VERSION ""

NS_ :

BS_:

BU_:

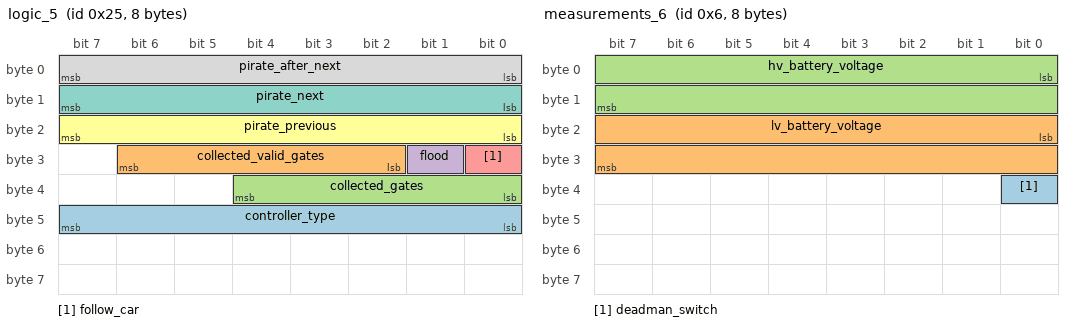
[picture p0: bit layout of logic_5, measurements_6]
BO_ 37 logic_5: 8 Vector__XXX
 SG_ controller_type : 40|8@1+ (1,0) [0|255] "" Vector__XXX
 SG_ collected_valid_gates : 26|5@1+ (1,0) [0|31] "" Vector__XXX
 SG_ collected_gates : 32|5@1+ (1,0) [0|31] "" Vector__XXX
 SG_ flood : 25|1@1+ (1,0) [0|0] "" Vector__XXX
 SG_ follow_car : 24|1@1+ (1,0) [0|0] "" Vector__XXX
 SG_ pirate_previous : 16|8@1+ (1,0) [0|255] "char" Vector__XXX
 SG_ pirate_next : 8|8@1+ (1,0) [0|255] "char" Vector__XXX
 SG_ pirate_after_next : 0|8@1+ (1,0) [0|255] "char" Vector__XXX

BO_ 6 measurements_6: 8 Vector__XXX
 SG_ deadman_switch : 32|1@1+ (1,0) [0|1] "" Vector__XXX
 SG_ lv_battery_voltage : 16|16@1+ (0.00025,0) [0|16.38375] "m" Vector__XXX
 SG_ hv_battery_voltage : 0|16@1+ (0.00025,0) [0|16.38375] "m" Vector__XXX

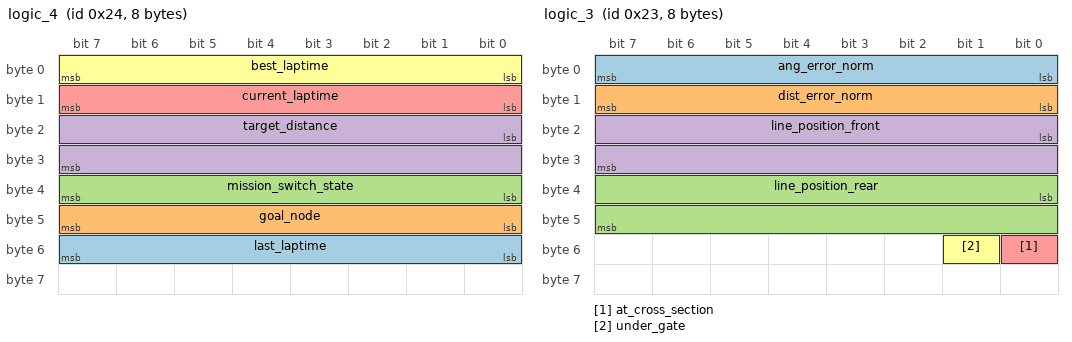
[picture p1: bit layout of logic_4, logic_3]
BO_ 36 logic_4: 8 Vector__XXX
 SG_ last_laptime : 48|8@1+ (0.01,0) [0|2.55] "s" Vector__XXX
 SG_ goal_node : 40|8@1+ (1,0) [0|255] "char" Vector__XXX
 SG_ mission_switch_state : 32|8@1+ (1,0) [0|255] "enum" Vector__XXX
 SG_ target_distance : 16|16@1+ (0.01,-327.675) [-327.675|327.675] "m" Vector__XXX
 SG_ current_laptime : 8|8@1+ (0.01,0) [0|2.55] "s" Vector__XXX
 SG_ best_laptime : 0|8@1+ (0.01,0) [0|2.55] "s" Vector__XXX

BO_ 35 logic_3: 8 Vector__XXX
 SG_ ang_error_norm : 0|8@1+ (0.004,0) [0|1.02] "" Vector__XXX
 SG_ dist_error_norm : 8|8@1+ (0.004,0) [0|1.02] "" Vector__XXX
 SG_ line_position_rear : 32|16@1+ (0.0005,-16.38375) [-16.38375|16.38375] "m" Vector__XXX
 SG_ line_position_front : 16|16@1+ (0.0005,-16.38375) [-16.38375|16.38375] "m" Vector__XXX
 SG_ at_cross_section : 48|1@1+ (1,0) [0|1] "" Vector__XXX
 SG_ under_gate : 49|1@1+ (1,0) [0|1] "" Vector__XXX

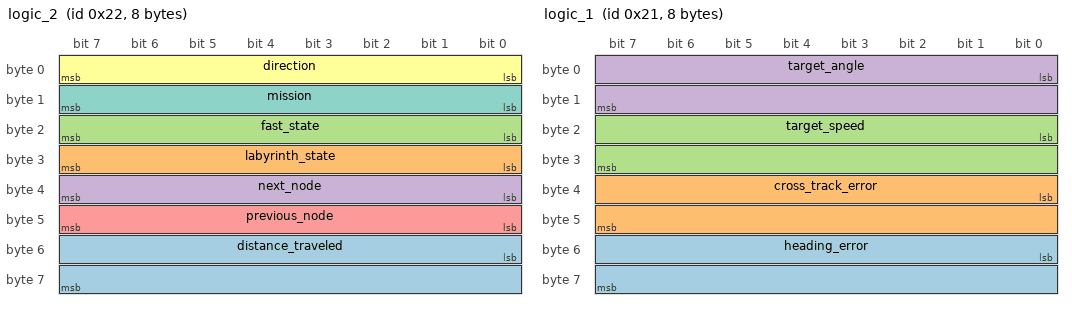
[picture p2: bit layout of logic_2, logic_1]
BO_ 34 logic_2: 8 Vector__XXX
 SG_ distance_traveled : 48|16@1+ (0.01,-327.675) [-327.675|327.675] "m" Vector__XXX
 SG_ labyrinth_state : 24|8@1+ (1,0) [0|255] "enum" Vector__XXX
 SG_ fast_state : 16|8@1+ (1,0) [0|255] "enum" Vector__XXX
 SG_ next_node : 32|8@1+ (1,0) [0|255] "char" Vector__XXX
 SG_ previous_node : 40|8@1+ (1,0) [0|255] "char" Vector__XXX
 SG_ direction : 0|8@1+ (1,0) [0|255] "enum" Vector__XXX
 SG_ mission : 8|8@1+ (1,0) [0|255] "enum" Vector__XXX

BO_ 2 measurements_2: 8 Vector__XXX
 SG_ line_sensor_9 : 16|2@1+ (1,0) [0|1] "" Vector__XXX
 SG_ line_sensor_8 : 14|2@1+ (1,0) [0|1] "" Vector__XXX
 SG_ line_sensor_7 : 12|2@1+ (1,0) [0|1] "" Vector__XXX
 SG_ line_sensor_6 : 10|2@1+ (1,0) [0|1] "" Vector__XXX
 SG_ line_sensor_5 : 8|2@1+ (1,0) [0|1] "" Vector__XXX
 SG_ line_sensor_4 : 6|2@1+ (1,0) [0|1] "" Vector__XXX
 SG_ line_sensor_32 : 62|2@1+ (1,0) [0|1] "" Vector__XXX
 SG_ line_sensor_31 : 60|2@1+ (1,0) [0|1] "" Vector__XXX
 SG_ line_sensor_30 : 58|2@1+ (1,0) [0|1] "" Vector__XXX
 SG_ line_sensor_3 : 4|2@1+ (1,0) [0|1] "" Vector__XXX
 SG_ line_sensor_29 : 56|2@1+ (1,0) [0|1] "" Vector__XXX
 SG_ line_sensor_28 : 54|2@1+ (1,0) [0|1] "" Vector__XXX
 SG_ line_sensor_27 : 52|2@1+ (1,0) [0|1] "" Vector__XXX
 SG_ line_sensor_26 : 50|2@1+ (1,0) [0|1] "" Vector__XXX
 SG_ line_sensor_25 : 48|2@1+ (1,0) [0|1] "" Vector__XXX
 SG_ line_sensor_24 : 46|2@1+ (1,0) [0|1] "" Vector__XXX
 SG_ line_sensor_23 : 44|2@1+ (1,0) [0|1] "" Vector__XXX
 SG_ line_sensor_22 : 42|2@1+ (1,0) [0|1] "" Vector__XXX
 SG_ line_sensor_21 : 40|2@1+ (1,0) [0|1] "" Vector__XXX
 SG_ line_sensor_20 : 38|2@1+ (1,0) [0|1] "" Vector__XXX
 SG_ line_sensor_2 : 2|2@1+ (1,0) [0|1] "" Vector__XXX
 SG_ line_sensor_19 : 36|2@1+ (1,0) [0|1] "" Vector__XXX
 SG_ line_sensor_18 : 34|2@1+ (1,0) [0|1] "" Vector__XXX
 SG_ line_sensor_17 : 32|2@1+ (1,0) [0|1] "" Vector__XXX
 SG_ line_sensor_16 : 30|2@1+ (1,0) [0|1] "" Vector__XXX
 SG_ line_sensor_15 : 28|2@1+ (1,0) [0|1] "" Vector__XXX
 SG_ line_sensor_14 : 26|2@1+ (1,0) [0|1] "" Vector__XXX
 SG_ line_sensor_13 : 24|2@1+ (1,0) [0|1] "" Vector__XXX
 SG_ line_sensor_12 : 22|2@1+ (1,0) [0|1] "" Vector__XXX
 SG_ line_sensor_11 : 20|2@1+ (1,0) [0|1] "" Vector__XXX
 SG_ line_sensor_10 : 18|2@1+ (1,0) [0|3] "" Vector__XXX
 SG_ line_sensor_1 : 0|2@1+ (1,0) [0|3] "" Vector__XXX

BO_ 33 logic_1: 8 Vector__XXX
 SG_ heading_error : 48|16@1+ (5E-005,-1.638375) [-1.638375|1.638375] "rad" Vector__XXX
 SG_ cross_track_error : 32|16@1+ (0.0001,-3.27675) [-3.27675|3.27675] "m" Vector__XXX
 SG_ target_speed : 16|16@1+ (0.0005,-16.38375) [-16.38375|16.38375] "m/s" Vector__XXX
 SG_ target_angle : 0|16@1+ (0.0001,-3.27675) [-3.27675|3.27675] "rad" Vector__XXX

BO_ 18 odometry_2: 8 Vector__XXX
 SG_ linear_velocity_x : 16|16@1+ (0.0005,-16.38375) [-16.38375|16.38375] "m/s" Vector__XXX
 SG_ angular_velocity_z : 0|16@1+ (0.0002,-6.5535) [-6.5535|6.5535] "rad/s" Vector__XXX

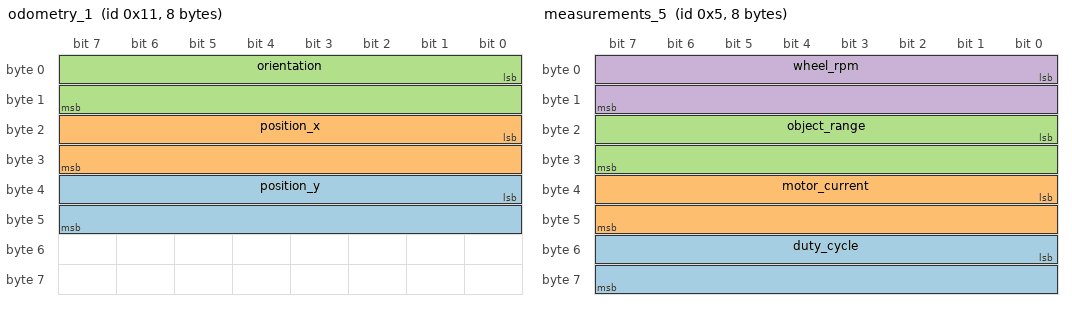
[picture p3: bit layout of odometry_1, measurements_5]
BO_ 17 odometry_1: 8 Vector__XXX
 SG_ position_y : 32|16@1+ (0.0005,-16.38375) [-16.38375|16.38375] "m" Vector__XXX
 SG_ position_x : 16|16@1+ (0.0005,-16.38375) [-16.38375|16.38375] "m" Vector__XXX
 SG_ orientation : 0|16@1+ (0.0002,-6.5535) [-6.5535|6.5535] "rad" Vector__XXX

BO_ 5 measurements_5: 8 Vector__XXX
 SG_ duty_cycle : 48|16@1+ (1.75E-005,0) [0|1.1468625] "" Vector__XXX
 SG_ motor_current : 32|16@1+ (0.001,0) [0|65.535] "A" Vector__XXX
 SG_ object_range : 16|16@1+ (0.0001,0) [0|6.5535] "m" Vector__XXX
 SG_ wheel_rpm : 0|16@1+ (0.1,-3276.75) [-3276.75|3276.75] "RPM" Vector__XXX

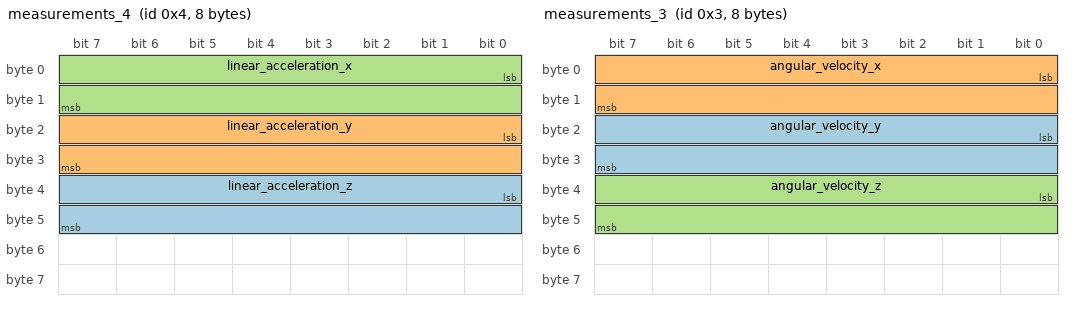
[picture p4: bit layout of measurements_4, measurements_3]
BO_ 4 measurements_4: 8 Vector__XXX
 SG_ linear_acceleration_z : 32|16@1+ (0.0005,-16.38375) [-16.38375|16.38375] "m/s^2" Vector__XXX
 SG_ linear_acceleration_y : 16|16@1+ (0.0005,-16.38375) [-16.38375|16.38375] "m/s^2" Vector__XXX
 SG_ linear_acceleration_x : 0|16@1+ (0.0005,-16.38375) [-16.38375|16.38375] "m/s^2" Vector__XXX

BO_ 3 measurements_3: 8 Vector__XXX
 SG_ angular_velocity_y : 16|16@1+ (0.0002,-6.5535) [-6.5535|6.5535] "rad/s" Vector__XXX
 SG_ angular_velocity_x : 0|16@1+ (0.0002,-6.5535) [-6.5535|6.5535] "rad/s" Vector__XXX
 SG_ angular_velocity_z : 32|16@1+ (0.0002,-6.5535) [-6.5535|6.5535] "rad/s" Vector__XXX

BO_ 1 measurements_1: 8 Vector__XXX
 SG_ line_sensor_9 : 16|2@1+ (1,0) [0|1] "" Vector__XXX
 SG_ line_sensor_8 : 14|2@1+ (1,0) [0|1] "" Vector__XXX
 SG_ line_sensor_7 : 12|2@1+ (1,0) [0|1] "" Vector__XXX
 SG_ line_sensor_6 : 10|2@1+ (1,0) [0|1] "" Vector__XXX
 SG_ line_sensor_5 : 8|2@1+ (1,0) [0|1] "" Vector__XXX
 SG_ line_sensor_4 : 6|2@1+ (1,0) [0|1] "" Vector__XXX
 SG_ line_sensor_32 : 62|2@1+ (1,0) [0|1] "" Vector__XXX
 SG_ line_sensor_31 : 60|2@1+ (1,0) [0|1] "" Vector__XXX
 SG_ line_sensor_30 : 58|2@1+ (1,0) [0|1] "" Vector__XXX
 SG_ line_sensor_3 : 4|2@1+ (1,0) [0|1] "" Vector__XXX
 SG_ line_sensor_29 : 56|2@1+ (1,0) [0|1] "" Vector__XXX
 SG_ line_sensor_28 : 54|2@1+ (1,0) [0|1] "" Vector__XXX
 SG_ line_sensor_27 : 52|2@1+ (1,0) [0|1] "" Vector__XXX
 SG_ line_sensor_26 : 50|2@1+ (1,0) [0|1] "" Vector__XXX
 SG_ line_sensor_25 : 48|2@1+ (1,0) [0|1] "" Vector__XXX
 SG_ line_sensor_24 : 46|2@1+ (1,0) [0|1] "" Vector__XXX
 SG_ line_sensor_23 : 44|2@1+ (1,0) [0|1] "" Vector__XXX
 SG_ line_sensor_22 : 42|2@1+ (1,0) [0|1] "" Vector__XXX
 SG_ line_sensor_21 : 40|2@1+ (1,0) [0|1] "" Vector__XXX
 SG_ line_sensor_20 : 38|2@1+ (1,0) [0|1] "" Vector__XXX
 SG_ line_sensor_2 : 2|2@1+ (1,0) [0|1] "" Vector__XXX
 SG_ line_sensor_19 : 36|2@1+ (1,0) [0|1] "" Vector__XXX
 SG_ line_sensor_18 : 34|2@1+ (1,0) [0|1] "" Vector__XXX
 SG_ line_sensor_17 : 32|2@1+ (1,0) [0|1] "" Vector__XXX
 SG_ line_sensor_16 : 30|2@1+ (1,0) [0|1] "" Vector__XXX
 SG_ line_sensor_15 : 28|2@1+ (1,0) [0|1] "" Vector__XXX
 SG_ line_sensor_14 : 26|2@1+ (1,0) [0|1] "" Vector__XXX
 SG_ line_sensor_13 : 24|2@1+ (1,0) [0|1] "" Vector__XXX
 SG_ line_sensor_12 : 22|2@1+ (1,0) [0|1] "" Vector__XXX
 SG_ line_sensor_11 : 20|2@1+ (1,0) [0|1] "" Vector__XXX
 SG_ line_sensor_10 : 18|2@1+ (1,0) [0|3] "" Vector__XXX
 SG_ line_sensor_1 : 0|2@1+ (1,0) [0|3] "" Vector__XXX

BA_DEF_  "BusType" STRING ;
BA_DEF_DEF_  "BusType" "";
BA_ "BusType" "CAN";
